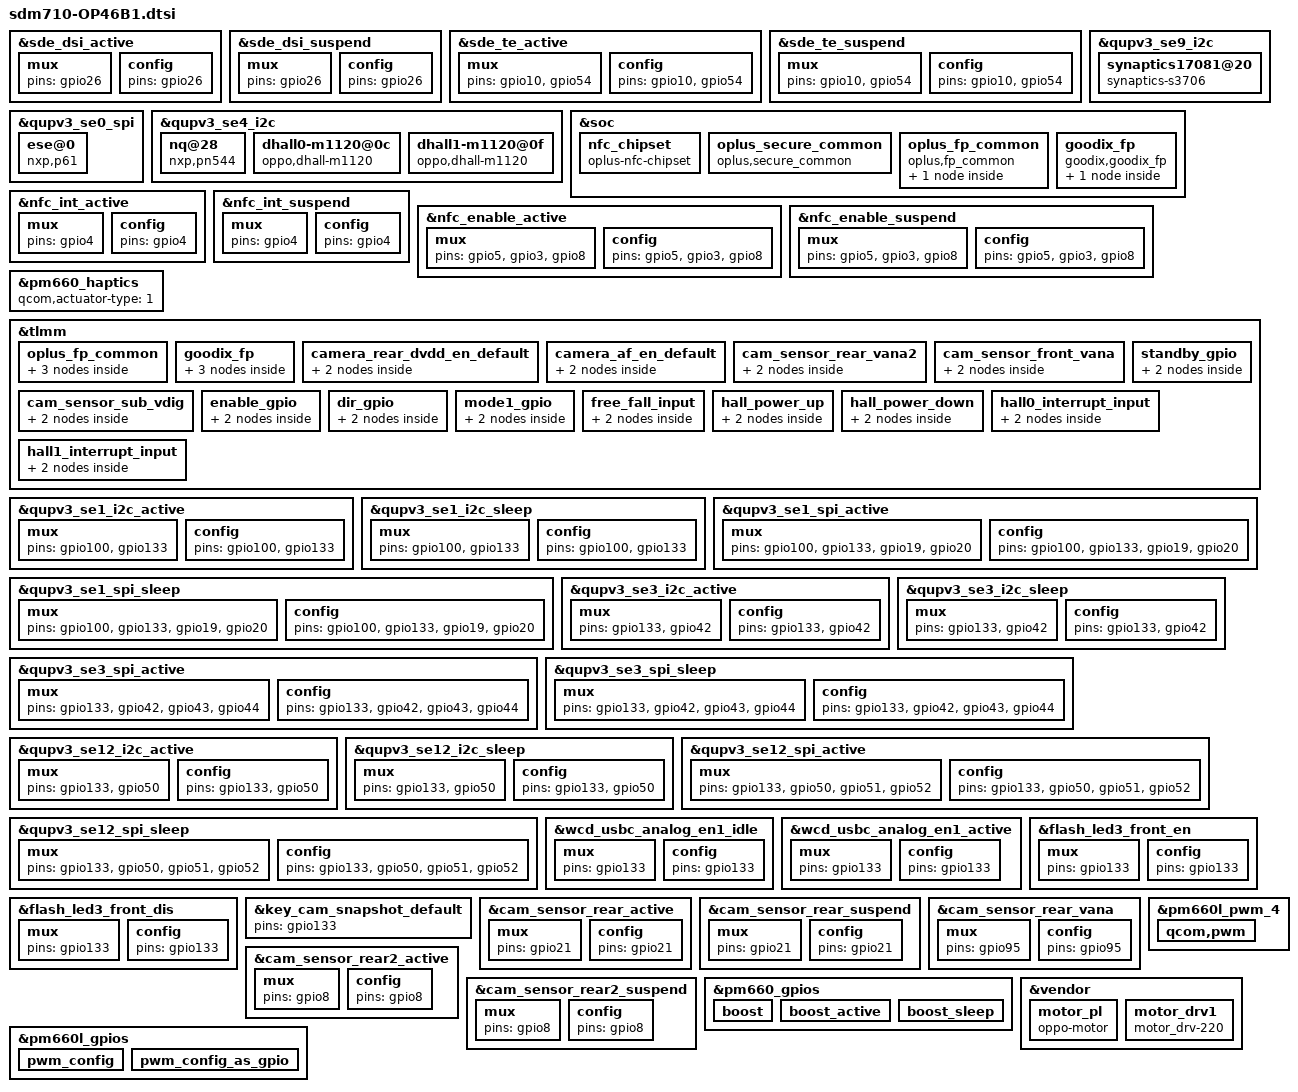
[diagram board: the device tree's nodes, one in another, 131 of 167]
/*
 * SPDX-FileCopyrightText: The LineageOS Project
 * SPDX-License-Identifier: Apache-2.0
 */

#include "sdm670-camera-sensor-OP46B1.dtsi"

/* SDE Display */
&sde_dsi_active {
	mux {
		pins = "gpio26";
	};

	config {
		pins = "gpio26";
	};
};

&sde_dsi_suspend {
	mux {
		pins = "gpio26";
	};

	config {
		pins = "gpio26";
	};
};

&sde_te_active {
	mux {
		pins = "gpio10", "gpio54";
	};

	config {
		pins = "gpio10", "gpio54";
	};
};

&sde_te_suspend {
	mux {
		pins = "gpio10", "gpio54";
	};

	config {
		pins = "gpio10", "gpio54";
	};
};

/* Synaptics S3706 Touchscreen */
&qupv3_se9_i2c {
	status = "okay";

	synaptics17081@20 {
		compatible = "synaptics-s3706";
		reg = <0x20>;
		chip-name = "S3706";

		/* Interrupt && Irq-gpio */
		interrupt-parent = <&tlmm>;
		interrupts = <125 0x00>;

		/* Power Config */
		enable2v8_gpio = <&pm660_gpios 13 0x1>;
		vdd_2v8-supply = <&pm660l_l2>;
		vcc_1v8-supply = <&pm660_l8>;
		vdd_2v8_volt = <2960000>;

		/* Other HW Resource */
		irq-gpio = <&tlmm 125 0x2008>;
		reset-gpio = <&tlmm 119 0x1>; // use gpio 199 for evt
		reset_t0-gpio = <&tlmm 99 0x1>; // use gpio 99 for t0
		pinctrl-names = "default";
		pinctrl-0 = <&ts_int_active &ts_reset_active>;

		touchpanel,max-num-support = <10>;
		touchpanel,tx-rx-num = <16 33>;
		touchpanel,panel-coords = <1080 2340>;
		touchpanel,display-coords = <1080 2340>;
		touchpanel,touchmajor-limit = <0 54>;

		platform_support_project = <18097 18098 18397>;
		platform_support_project_dir = <18097 18097 18097>;
		platform_support_project_commandline = "default_commandline", "default_commandline", "default_commandline";

		/* SW Support Feature Control */
		black_gesture_support;
		fw_edge_limit_support;
		fw_corner_limit_support;
		// spurious_fingerprint_support;
		charger_pump_support;
		game_switch_support;
		face_detect_support;
		smart_gesture_support;
		pressure_report_support;
		fw_update_app_support;
		fingerprint_underscreen_support;
		rt155_fdreplace_rt59_support;
		report_point_first_support;
		report_120hz_support;
		health_monitor_v2_support;
		/*
		 * Virtual Key Config:
		 * 1:touchpanel,button-type: <virtualkey_type  supportted_button-map>
		 * virtualkey_type:
		 * Type 1: using board_properties
		 * Type 2: using same IC (button zone&& touch zone are seprate)
		 * Type 3: using diffrent IC (button zone&& touch zone are seprate)
		 * Type 4: No need of virtual key process
		 * supportted_button-map:select|menu|home|back
		 *
		 * 2:touchpanel,button-map
		 * type (X1,Y1)(X2,Y2)(X3,Y3)(Width_X,Hight_Y)--Only when button-type is 0
		 */
		touchpanel,button-type = <4>;
		touchpanel.button-TRx = <0 0>;
	};
};

/* NXP PN544 NFC */
&qupv3_se0_spi {
	status = "okay";

	ese@0 {
		compatible = "nxp,p61";
		reg = <0>;
		spi-max-frequency = <8000000>;
	};
};

&qupv3_se4_i2c {
	nq@28 {
		compatible = "nxp,pn544";
		reg = <0x28>;
		nxp,pn544-irq = <&pm660l_gpios 4 0x00>;
		nxp,pn544-ven = <&pm660l_gpios 5 0x00>;
		nxp,pn544-fw-dwnld = <&pm660l_gpios 3 0x00>;
		nxp,pn544-ese-pwr = <&pm660l_gpios 8 0x00>;
		qcom,nq-clkreq = <&pm660_gpios 4 0x00>;
		interrupt-parent = <&pm660l_gpios>;
		qcom,clk-src = "BBCLK3";
		interrupts = <4 0>;
		interrupt-names = "nfc_irq";
		pinctrl-names = "nfc_default";
		pinctrl-0 = <&nfc_clk_default>;
		clocks = <&clock_rpmh RPMH_LN_BB_CLK3>;
		clock-names = "ref_clk";
	};
};

&soc {
	nfc_chipset {
		compatible = "oplus-nfc-chipset";
		chipset-18097 = "NQ330";
		chipset-18098 = "NQ330";
		chipset-18397 = "NQ330";
	};
};

&nfc_int_active {
	mux {
		/* GPIO 4 NFC Read Interrupt */
		pins = "gpio4";
	};

	config {
		pins = "gpio4";
	};
};

&nfc_int_suspend {
	mux {
		/* GPIO 4 NFC Read Interrupt */
		pins = "gpio4";
	};

	config {
		pins = "gpio4";
	};
};

&nfc_enable_active {
	mux {
		/* 5: NFC ENABLE 3: FW DNLD */
		/* 8: ESE Enable */
		pins = "gpio5", "gpio3", "gpio8";
	};

	config {
		pins = "gpio5", "gpio3", "gpio8";
	};
};

&nfc_enable_suspend {
	mux {
		/* 5: NFC ENABLE 3: FW DNLD */
		/* 8: ESE Enable */
		pins = "gpio5", "gpio3", "gpio8";
	};

	config {
		pins = "gpio5", "gpio3", "gpio8";
	};
};

/* ERM Vibrator */
&pm660_haptics {
	qcom,actuator-type = <1>;
};

/* Goodix optical fingerprint */
&soc {
	oplus_secure_common {
		compatible = "oplus,secure_common";
	};

	oplus_fp_common {
		compatible = "oplus,fp_common"; // Manufacture, and Model
		oplus,fp_gpio_num = <1>; /* the gpio number of fingerprint id used */
		oplus,fp_gpio_0 = <&tlmm 23 0x0>; // 0: silead,1:goodix,empty:no id pin
		pinctrl-names = "default";
		pinctrl-0 = <&gpio_id2_default>;

		goodix_optical {
			oplus,fp-id = <1>; /* fp id mapping table */
			vendor-chip = <11>; /* please refer to the struct fp_vendor_t in oppo_fp_commmon.n */
			eng-menu = "-1,-1"; /* represents SNR, inclination test item in engineer menu, and 0/1 means off/on */
			chip-name = "G_OPTICAL_G2";  /* /proc/fp_id, will be displayed in engineer menu  */
		};
	};

	goodix_fp {
		compatible = "goodix,goodix_fp";
		power-mode = <1> ; /* please refer to the struct fp_power_mode_t in oppo_fp_commmon.n ,0: power mode not set, 1: ldo power, 2: gpio power, 3: auto power */
		ldo-supply = <&pm660l_l5>; // pm660l_l5 for goodix_fp
		ldo-config = <2960000 2960000 150000>;
		gpio-power = <&tlmm 2 0x0>;
		goodix,gpio_irq = <&tlmm 121 0x1>;
		goodix,gpio_reset = <&tlmm 80 0x0>;
		pinctrl-names = "default";
		pinctrl-0 = <&gpio_goodix_irq_default>;
		ftm_poweroff_flag = <0>;
		notify_tpinfo_flag = <0>;

		power-num = <1> ;
		power_source_1 {
			power-mode = <1>;   /* 1 = ldo power, refer to oplus_fp_common.h */
			power-name = "ldo";
			power-config = "ldo-config";
			delay-time = <0>;
		};
	};
};

&tlmm {
	oplus_fp_common {
		gpio_id2_default: gpio_id2_default {
			mux {
				pins = "gpio23";
				function = "gpio";
			};

			config {
				pins = "gpio23";
				drive-strength = <2>;
				bias-pull-up;
				input-enable;
			};
		};
	};

	goodix_fp {
		gpio_goodix_irq_default: gpio_goodix_irq_default {
			mux {
				pins = "gpio121";
				function = "gpio";
			};

			config {
				pins = "gpio121";
				drive-strength = <2>;
				bias-disable;
				input-enable;
			};
		};
	};
};

/* Pinctrl */
&qupv3_se1_i2c_active {
	mux {
		pins = "gpio100", "gpio133";
	};

	config {
		pins = "gpio100", "gpio133";
	};
};

&qupv3_se1_i2c_sleep {
	mux {
		pins = "gpio100", "gpio133";
	};

	config {
		pins = "gpio100", "gpio133";
	};
};

&qupv3_se1_spi_active {
	mux {
		pins = "gpio100", "gpio133", "gpio19",
					"gpio20";
	};

	config {
		pins = "gpio100", "gpio133", "gpio19",
					"gpio20";
	};
};

&qupv3_se1_spi_sleep {
	mux {
		pins = "gpio100", "gpio133", "gpio19",
					"gpio20";
	};

	config {
		pins = "gpio100", "gpio133", "gpio19",
					"gpio20";
	};
};

&qupv3_se3_i2c_active {
	mux {
		pins = "gpio133", "gpio42";
	};

	config {
		pins = "gpio133", "gpio42";
	};
};

&qupv3_se3_i2c_sleep {
	mux {
		pins = "gpio133", "gpio42";
	};

	config {
		pins = "gpio133", "gpio42";
	};
};

&qupv3_se3_spi_active {
	mux {
		pins = "gpio133", "gpio42", "gpio43",
					"gpio44";
	};

	config {
		pins = "gpio133", "gpio42", "gpio43",
					"gpio44";
	};
};

&qupv3_se3_spi_sleep {
	mux {
		pins = "gpio133", "gpio42", "gpio43",
					"gpio44";
	};

	config {
		pins = "gpio133", "gpio42", "gpio43",
					"gpio44";
	};
};

&qupv3_se12_i2c_active {
	mux {
		pins = "gpio133", "gpio50";
	};

	config {
		pins = "gpio133", "gpio50";
	};
};

&qupv3_se12_i2c_sleep {
	mux {
		pins = "gpio133", "gpio50";
	};

	config {
		pins = "gpio133", "gpio50";
	};
};

&qupv3_se12_spi_active {
	mux {
		pins = "gpio133", "gpio50", "gpio51",
					"gpio52";
	};

	config {
		pins = "gpio133", "gpio50", "gpio51",
					"gpio52";
	};
};

&qupv3_se12_spi_sleep {
	mux {
		pins = "gpio133", "gpio50", "gpio51",
					"gpio52";
	};

	config {
		pins = "gpio133", "gpio50", "gpio51",
					"gpio52";
	};
};

&wcd_usbc_analog_en1_idle {
	mux {
		pins = "gpio133";
	};

	config {
		pins = "gpio133";
	};
};

&wcd_usbc_analog_en1_active {
	mux {
		pins = "gpio133";
	};

	config {
		pins = "gpio133";
	};
};

/* Camera */
&flash_led3_front_en {
	mux {
		pins = "gpio133";
	};

	config {
		pins = "gpio133";
	};
};

&flash_led3_front_dis {
	mux {
		pins = "gpio133";
	};

	config {
		pins = "gpio133";
	};
};

&key_cam_snapshot_default {
	pins = "gpio133";
};

&cam_sensor_rear_active {
	mux {
		pins = "gpio21";
	};

	config {
		pins = "gpio21";
	};
};

&cam_sensor_rear_suspend {
	mux {
		pins = "gpio21";
	};

	config {
		pins = "gpio21";
	};
};

&cam_sensor_rear_vana {
	mux {
		pins = "gpio95";
	};

	config {
		pins = "gpio95";
	};
};

&cam_sensor_rear2_active {
	mux {
		pins = "gpio8";
	};

	config {
		pins = "gpio8";
	};
};

&cam_sensor_rear2_suspend {
	mux {
		pins = "gpio8";
	};

	config {
		pins = "gpio8";
	};
};

&tlmm {
	camera_rear_dvdd_en_default: camera_rear_dvdd_en_default {
		/* sub VDIG LDO */
		mux {
			pins = "gpio41";
			function = "gpio";
		};

		config {
			pins = "gpio41";
			bias-disable; /* No PULL */
			drive-strength = <2>; /* 2 MA */
		};
	};

	camera_af_en_default: camera_af_en_default {
		/* sub VDIG LDO */
		mux {
			pins = "gpio49";
			function = "gpio";
		};

		config {
			pins = "gpio49";
			bias-disable; /* No PULL */
			drive-strength = <2>; /* 2 MA */
		};
	};

	cam_sensor_rear_vana2: cam_sensor_rear_vana2 {
		/* AVDD LDO */
		mux {
			pins = "gpio136";
			function = "gpio";
		};

		config {
			pins = "gpio136";
			bias-disable; /* No PULL */
			drive-strength = <2>; /* 2 MA */
		};
	};

	cam_sensor_front_vana: cam_sensor_front_vana {
		/* AVDD LDO */
		mux {
			pins = "gpio39";
			function = "gpio";
		};

		config {
			pins = "gpio39";
			bias-disable; /* No PULL */
			drive-strength = <2>; /* 2 MA */
		};
	};

	cam_sensor_sub_vdig: cam_sensor_sub_vdig {
		/* sub VDIG LDO */
		mux {
			pins = "gpio116";
			function = "gpio";
		};

		config {
			pins = "gpio116";
			bias-disable; /* No PULL */
			drive-strength = <2>; /* 2 MA */
		};
	};
};

/* Motor */
&qupv3_se4_i2c {
	dhall0-m1120@0c {
		compatible = "oppo,dhall-m1120";
		reg = <0x0c>;
		pinctrl-names = "hall_power_down","hall_power_up","hall0_interrupt_input";
		pinctrl-0 = <&hall_power_down>;
		pinctrl-1 = <&hall_power_up>;
		pinctrl-2 = <&hall0_interrupt_input>;
		interrupt-parent = <&tlmm>;
		interrupts = <122 0x2>;
		dhall,irq-gpio = <&tlmm 122 0x2008>;
		dhall,id = <0>;
		vdd_2v8-supply = <&pm660l_l3>; // VREG_L3B_3P0
		vcc_1v8-supply = <&pm660_l14>; // VREG_L14A_1P8
		qcom,hall-power-gpio = <&tlmm 65 0>;
	};

	dhall1-m1120@0f {
		compatible = "oppo,dhall-m1120";
		reg = <0x0f>;
		pinctrl-names = "hall_power_down","hall_power_up","hall1_interrupt_input";
		pinctrl-0 = <&hall_power_down>;
		pinctrl-1 = <&hall_power_up>;
		pinctrl-2 = <&hall1_interrupt_input>;
		interrupt-parent = <&tlmm>;
		interrupts = <42 0x2>;
		dhall,irq-gpio = <&tlmm 42 0x2008>;
		dhall,id = <1>;
		vdd_2v8-supply = <&pm660l_l3>; // VREG_L19A_3P0
		vcc_1v8-supply = <&pm660_l14>; // VREG_S4A_1P8
		qcom,hall-power-gpio = <&tlmm 65 0>;
	};
};

&pm660_gpios {
	boost: boost {
		pins = "gpio11";
		function = "normal";
		bias-pull-down; // pull down
		power-source = <0>; // VIN0, 1.8V
		output-low; // digital output, no invert
		qcom,drive-strength = <3>; // 0.15
	};

	boost_active:boost_active {
		pins = "gpio11";
		function = "normal";
		bias-disable; // pull down
		power-source = <0>; // VIN0, 1.8V
		output-high; // digital output, no invert
		qcom,drive-strength = <3>; // 0.15
	};

	boost_sleep:boost_sleep {
		pins = "gpio11";
		function = "normal";
		bias-pull-down; // pull down
		power-source = <0>; // VIN0, 1.8V
		output-low; // digital output, no invert
		qcom,drive-strength = <3>; // 0.15
	};
};

&pm660l_gpios {
	// pwm mode
	pwm_config: pwm_config {
		pins = "gpio6"; // GPIO 8
		function = "func1"; // Special Function 1,pwm
		bias-disable; // No Pull
		power-source = <0>; // VIN0
		output-low; // digital output, no invert
		qcom,drive-strength = <3>; // LOW strength
		drive-push-pull; // CMOS
	};

	// gpio mode for stspin220
	pwm_config_as_gpio: pwm_config_as_gpio {
		pins = "gpio6"; // GPIO 8
		function = "normal";
		bias-disable; // No Pull
		power-source = <0>; // VIN0
		output-low; // digital output, no invert
		qcom,drive-strength = <3>; // LOW strength
		drive-push-pull; // CMOS
	};
};

&pm660l_pwm_4 {
	qcom,ramp-index = <1>;
	qcom,mode-select = <0>; /* PWM */
	qcom,period = <7>;
	#pwm-cells = <2>;
	status = "okay";
	qcom,pwm {
		qcom,duty = <3>;
		label = "pwm";
	};
};

&tlmm {
	standby_gpio: standby_gpio {
		mux {
			pins = "gpio44";
			function = "gpio";
		};

		config {
			pins = "gpio44";
			drive-strength = <2>;
			bias-disable;
			output-low;
		};
	};

	enable_gpio: enable_gpio {
		mux {
			pins = "gpio43";
			function = "gpio";
		};

		config {
			pins = "gpio43";
			drive-strength = <2>;
			bias-disable;
			output-low;
		};
	};

	dir_gpio: dir_gpio {
		mux {
			pins = "gpio94";
			function = "gpio";
		};

		config {
			pins = "gpio94";
			drive-strength = <2>;
			bias-disable;
			output-low;
		};
	};

	mode1_gpio: mode1_gpio {
		mux {
			pins = "gpio66";
			function = "gpio";
		};

		config {
			pins = "gpio66";
			drive-strength = <2>;
			bias-disable;
			output-low;
		};
	};

	free_fall_input: free_fall_input {
		mux {
			pins = "gpio68";
			function = "gpio";
		};

		config {
			pins = "gpio68";
			drive-strength = <2>;
			input-enable;
			bias-disable; // No Pull
		};
	};

	hall_power_up: hall_power_up {
		mux {
			pins = "gpio65";
			function = "gpio";
		};

		config {
			pins = "gpio65";
			drive-strength = <2>;
			output-high;
			bias-pull-down;
		};
	};

	hall_power_down: hall_power_down {
		mux {
			pins = "gpio65";
			function = "gpio";
		};

		config {
			pins = "gpio65";
			drive-strength = <2>;
			output-low;
			bias-pull-down;
		};
	};

	hall0_interrupt_input: hall0_interrupt_input {
		mux {
			pins = "gpio122";
			function = "gpio";
		};

		config {
			pins = "gpio122";
			drive-strength = <2>;
			input-enable;
			bias-pull-up; // Pull up
		};
	};

	hall1_interrupt_input: hall1_interrupt_input {
		mux {
			pins = "gpio42";
			function = "gpio";
		};

		config {
			pins = "gpio42";
			drive-strength = <2>;
			input-enable;
			bias-pull-up; // Pull up
		};
	};
};

&vendor  {
	motor_pl: motor_pl {
		compatible = "oppo-motor";
		interrupt-parent = <&tlmm>;
		interrupts = <68 0x2>;
		motor,irq-gpio = <&tlmm 68 0x2008>;
		pinctrl-names = "free_fall_input";
		pinctrl-0 = <&free_fall_input>;
		hall-irq-pos = <170>;
		motor-retard-pos = <430>;
		terminal-offset = <7 34>;
		delay-cycle = <13 30 23>; // ms
		slow-delay-cycle = <28 28 28>; // ms
		full-speed-param = <68 15500>;
		up-speed-param = <25 15500>;
		down-speed-param = <2 156250>;
		slow-full-speed-param = <58 31250>;
		slow-up-speed-param = <15 104166>;
		slow-down-speed-param = <2 156250>;
		stop-neg-point = <4 4>;
		stop-pos-point = <4 4>;
		hall-data-sign = <0>; // 1 represent positive, 0 represent negative
		press-irq-makeup = <55 55>;
		extre_stop_support;
		monotonicity-offset = <25>;
		cali-retard-offset = <15 40>;
		hall-max-thrd = <0 0>;
		mag_noise_support;
		mag_noise_pattern = <100 513 1 513 200 1 1>;
	};

	motor_drv1: motor_drv1 {
		compatible = "motor_drv-220";
		pinctrl-names = "boost","pwm_config","pwm_config_as_gpio","enable_gpio","dir_gpio","standby_gpio","mode1_gpio","motor_active","motor_sleep";
		pinctrl-0 = <&boost>;
		pinctrl-1 = <&pwm_config>;
		pinctrl-2 = <&pwm_config_as_gpio>;
		pinctrl-3 = <&enable_gpio>;
		pinctrl-4 = <&dir_gpio>;
		pinctrl-5 = <&standby_gpio>;
		pinctrl-6 = <&mode1_gpio>;
		pinctrl-7 = <&boost_active>;
		pinctrl-8 = <&boost_sleep>;
		pwms = <&pm660l_pwm_4 0 0>;
		boost-gpio = <&pm660_gpios 11 0x00>;
		standby-gpio = <&tlmm 44 0>;
		dir-gpio = <&tlmm 94 0>;
		enable-gpio =  <&tlmm 43 0>;
		step-gpio = <&pm660l_gpios 6 0>;
		mode1-gpio = <&tlmm 66 0>;
		ratio-a = <24>;
		ratio-b = <1840>; // 18.40
		ratio-c = <20>;
		ratio-d = <32>;
	};
};
